AUTOSAR XML (schema 00046)
package /ComponentTypes
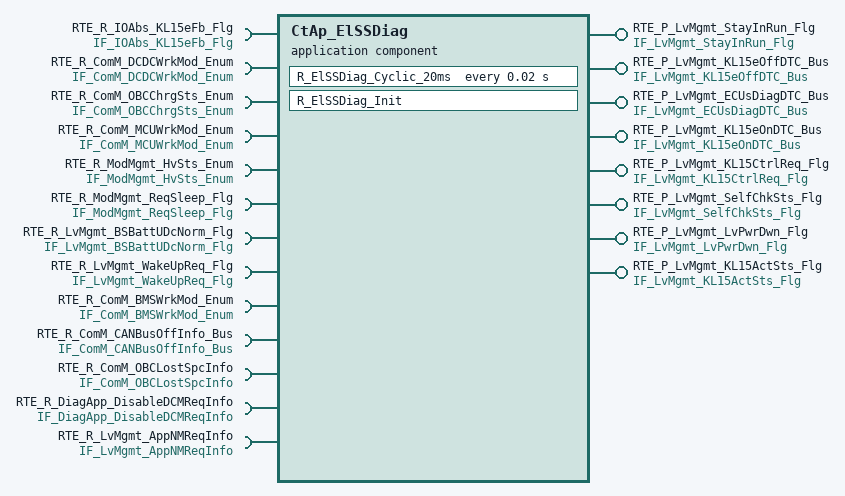
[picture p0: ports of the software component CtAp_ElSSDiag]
  application sw component type CtAp_ElSSDiag
    8 x require port:
      RTE_R_IOAbs_KL15eFb_Flg: nonqueued-receiver-com-spec{data-element=tec_IOAbs_KL15eFb_Flg, filter=data-filter-type=ALWAYS, init-value=0}, required-interface=IF_IOAbs_KL15eFb_Flg
      RTE_R_ComM_DCDCWrkMod_Enum: nonqueued-receiver-com-spec{data-element=tec_ComM_DCDCWrkMod_Enum, filter=data-filter-type=ALWAYS, init-value=0}, required-interface=IF_ComM_DCDCWrkMod_Enum
      RTE_R_ComM_OBCChrgSts_Enum: nonqueued-receiver-com-spec{data-element=tec_ComM_OBCChrgSts_Enum, filter=data-filter-type=ALWAYS, init-value=0}, required-interface=IF_ComM_OBCChrgSts_Enum
      RTE_R_ComM_MCUWrkMod_Enum: nonqueued-receiver-com-spec{data-element=tec_ComM_MCUWrkMod_Enum, filter=data-filter-type=ALWAYS, init-value=0}, required-interface=IF_ComM_MCUWrkMod_Enum
      RTE_R_ModMgmt_HvSts_Enum: nonqueued-receiver-com-spec{data-element=tec_ModMgmt_HvSts_Enum, filter=data-filter-type=ALWAYS, init-value=0}, required-interface=IF_ModMgmt_HvSts_Enum
      RTE_R_ModMgmt_ReqSleep_Flg: nonqueued-receiver-com-spec{data-element=tec_ModMgmt_ReqSleep_Flg, filter=data-filter-type=ALWAYS, init-value=0}, required-interface=IF_ModMgmt_ReqSleep_Flg
      RTE_R_LvMgmt_BSBattUDcNorm_Flg: nonqueued-receiver-com-spec{data-element=tec_LvMgmt_BSBattUDcNorm_Flg, filter=data-filter-type=ALWAYS, init-value=0}, required-interface=IF_LvMgmt_BSBattUDcNorm_Flg
      RTE_R_LvMgmt_WakeUpReq_Flg: nonqueued-receiver-com-spec{data-element=tec_LvMgmt_WakeUpReq_Flg, filter=data-filter-type=ALWAYS, init-value=0}, required-interface=IF_LvMgmt_WakeUpReq_Flg
    8 x provide port:
      RTE_P_LvMgmt_StayInRun_Flg: nonqueued-sender-com-spec{data-element=tec_LvMgmt_StayInRun_Flg, init-value=0}, provided-interface=IF_LvMgmt_StayInRun_Flg
      RTE_P_LvMgmt_KL15eOffDTC_Bus: nonqueued-sender-com-spec{data-element=tec_LvMgmt_KL15eOffDTC_Bus, init-value=fields=[LvMgmt_MonStatKL15eOffDTC:0, LvMgmt_MonResKL15eOffDTC:0, LvMgmt_ErrStatKL15eOffDTC:0, LvMgmt_ErrResKL15eOffDTC:0]}, provided-interface=IF_LvMgmt_KL15eOffDTC_Bus
      RTE_P_LvMgmt_ECUsDiagDTC_Bus: nonqueued-sender-com-spec{data-element=tec_LvMgmt_ECUsDiagDTC_Bus, init-value=fields=[LvMgmt_MonStatECUsDiagDTC:0, LvMgmt_MonResECUsDiagDTC:0, LvMgmt_ErrStatECUsDiagDTC:0, LvMgmt_ErrResECUsDiagDTC:0]}, provided-interface=IF_LvMgmt_ECUsDiagDTC_Bus
      RTE_P_LvMgmt_KL15eOnDTC_Bus: nonqueued-sender-com-spec{data-element=tec_LvMgmt_KL15eOnDTC_Bus, init-value=fields=[LvMgmt_MonStatKL15eOnDTC_:0, LvMgmt_MonResKL15eOnDTC:0, LvMgmt_ErrStatKL15eOnDTC:0, LvMgmt_ErrResKL15eOnDTC:0]}, provided-interface=IF_LvMgmt_KL15eOnDTC_Bus
      RTE_P_LvMgmt_KL15CtrlReq_Flg: nonqueued-sender-com-spec{data-element=tec_LvMgmt_KL15CtrlReq_Flg, init-value=0}, provided-interface=IF_LvMgmt_KL15CtrlReq_Flg
      RTE_P_LvMgmt_SelfChkSts_Flg: nonqueued-sender-com-spec{data-element=tec_LvMgmt_SelfChkSts_Flg, init-value=0}, provided-interface=IF_LvMgmt_SelfChkSts_Flg
      RTE_P_LvMgmt_LvPwrDwn_Flg: nonqueued-sender-com-spec{data-element=tec_LvMgmt_LvPwrDwn_Flg, init-value=0}, provided-interface=IF_LvMgmt_LvPwrDwn_Flg
      RTE_P_LvMgmt_KL15ActSts_Flg: nonqueued-sender-com-spec{data-element=tec_LvMgmt_KL15ActSts_Flg, init-value=0}, provided-interface=IF_LvMgmt_KL15ActSts_Flg
    5 x require port:
      RTE_R_ComM_BMSWrkMod_Enum: nonqueued-receiver-com-spec{data-element=tec_ComM_BMSWrkMod_Enum, filter=data-filter-type=ALWAYS, init-value=0}, required-interface=IF_ComM_BMSWrkMod_Enum
      RTE_R_ComM_CANBusOffInfo_Bus: required-interface=IF_ComM_CANBusOffInfo_Bus
        required-com-specs:
          data-element=tec_ComM_EPTCANBusOffInfo_Bus, filter=data-filter-type=ALWAYS, init-value=fields=[ComM_MonStatEPTCANBusOffInfo:0, ComM_MonResEPTCANBusOffInfo:0, ComM_ErrStatEPTCANBusOffInfo:0, ComM_ErrResEPTCANBusOffInfo:0]
          data-element=tec_ComM_CHCANBusOffInfo_Bus, filter=data-filter-type=ALWAYS, init-value=fields=[ComM_MonStatCHCANBusOffInfo:0, ComM_MonResCHCANBusOffInfo:0, ComM_ErrStatCHCANBusOffInfo:0, ComM_ErrResCHCANBusOffInfo:0]
          data-element=tec_ComM_EPTCANBusOffDTCInfo_Bus, filter=data-filter-type=ALWAYS, init-value=fields=[ComM_MonStatEPTCANBusOffDTCInfo:0, ComM_MonResEPTCANBusOffDTCInfo:0, ComM_ErrStatEPTCANBusOffDTCInfo:0, ComM_ErrResEPTCANBusOffDTCInfo:0]
          data-element=tec_ComM_CHCANBusOffDTCInfo_Bus, filter=data-filter-type=ALWAYS, init-value=fields=[ComM_MonStatCHCANBusOffDTCInfo:0, ComM_MonResCHCANBusOffDTCInfo:0, ComM_ErrStatCHCANBusOffDTCInfo:0, ComM_ErrResCHCANBusOffDTCInfo:0]
          data-element=tec_ComM_DCCANBusOffDTCInfo_Bus, init-value=fields=[ComM_MonStatDCCANDTCBusOffInfo:0, ComM_MonResDCCANDTCBusOffInfo:0, ComM_ErrStatDCCANDTCBusOffInfo:0, ComM_ErrResDCCANDTCBusOffInfo:0]
          data-element=tec_ComM_DCCANBusOffInfo_Bus, init-value=fields=[ComM_MonStatDCCANBusOffInfo:0, ComM_MonResDCCANBusOffInfo:0, ComM_ErrStatDCCANBusOffInfo:0, ComM_ErrResDCCANBusOffInfo:0]
      RTE_R_ComM_OBCLostSpcInfo: nonqueued-receiver-com-spec{data-element=tec_ComM_OBCLostSpcInfo, filter=data-filter-type=ALWAYS, init-value=0}, required-interface=IF_ComM_OBCLostSpcInfo
      RTE_R_DiagApp_DisableDCMReqInfo: nonqueued-receiver-com-spec{data-element=tec_DiagApp_DisableDCMReqInfo, filter=data-filter-type=ALWAYS, init-value=0}, required-interface=IF_DiagApp_DisableDCMReqInfo
      RTE_R_LvMgmt_AppNMReqInfo: nonqueued-receiver-com-spec{data-element=tec_LvMgmt_AppNMReqInfo, filter=data-filter-type=ALWAYS, init-value=0}, required-interface=IF_LvMgmt_AppNMReqInfo
    behavior CtAp_ElSSDiag_InternalBehavior
      timing event TMT_R_ElSSDiag_Cyclic_20ms: start-on-event=R_ElSSDiag_Cyclic_20ms, period=0.02
      init event CtAp_ElSSDiag_InitEvent: start-on-event=R_ElSSDiag_Init
      runnable R_ElSSDiag_Cyclic_20ms
        data-receive-point-by-arguments:
          13 x access:
            REC_RTE_R_ComM_BMSWrkMod_Enum_tec_ComM_BMSWrkMod_Enum: accessed-variable=RTE_R_ComM_BMSWrkMod_Enum.tec_ComM_BMSWrkMod_Enum
            REC_RTE_R_ComM_DCDCWrkMod_Enum_tec_ComM_DCDCWrkMod_Enum: accessed-variable=RTE_R_ComM_DCDCWrkMod_Enum.tec_ComM_DCDCWrkMod_Enum
            REC_RTE_R_ComM_MCUWrkMod_Enum_tec_ComM_MCUWrkMod_Enum: accessed-variable=RTE_R_ComM_MCUWrkMod_Enum.tec_ComM_MCUWrkMod_Enum
            REC_RTE_R_ComM_OBCChrgSts_Enum_tec_ComM_OBCChrgSts_Enum: accessed-variable=RTE_R_ComM_OBCChrgSts_Enum.tec_ComM_OBCChrgSts_Enum
            REC_RTE_R_IOAbs_KL15eFb_Flg_tec_IOAbs_KL15eFb_Flg: accessed-variable=RTE_R_IOAbs_KL15eFb_Flg.tec_IOAbs_KL15eFb_Flg
            REC_RTE_R_LvMgmt_BSBattUDcNorm_Flg_tec_LvMgmt_BSBattUDcNorm_Flg: accessed-variable=RTE_R_LvMgmt_BSBattUDcNorm_Flg.tec_LvMgmt_BSBattUDcNorm_Flg
            REC_RTE_R_LvMgmt_WakeUpReq_Flg_tec_LvMgmt_WakeUpReq_Flg: accessed-variable=RTE_R_LvMgmt_WakeUpReq_Flg.tec_LvMgmt_WakeUpReq_Flg
            REC_RTE_R_ModMgmt_HvSts_Enum_tec_ModMgmt_HvSts_Enum: accessed-variable=RTE_R_ModMgmt_HvSts_Enum.tec_ModMgmt_HvSts_Enum
            REC_RTE_R_ModMgmt_ReqSleep_Flg_tec_ModMgmt_ReqSleep_Flg: accessed-variable=RTE_R_ModMgmt_ReqSleep_Flg.tec_ModMgmt_ReqSleep_Flg
            REC_RTE_R_ComM_CANBusOffInfo_Bus_tec_ComM_EPTCANBusOffInfo_Bus: accessed-variable=RTE_R_ComM_CANBusOffInfo_Bus.tec_ComM_EPTCANBusOffInfo_Bus
            REC_RTE_R_ComM_OBCLostSpcInfo_tec_ComM_OBCLostSpcInfo: accessed-variable=RTE_R_ComM_OBCLostSpcInfo.tec_ComM_OBCLostSpcInfo
            REC_RTE_R_DiagApp_DisableDCMReqInfo_tec_DiagApp_DisableDCMReqInfo: accessed-variable=RTE_R_DiagApp_DisableDCMReqInfo.tec_DiagApp_DisableDCMReqInfo
            REC_RTE_R_LvMgmt_AppNMReqInfo_tec_LvMgmt_AppNMReqInfo: accessed-variable=RTE_R_LvMgmt_AppNMReqInfo.tec_LvMgmt_AppNMReqInfo
        data-send-points:
          8 x access:
            SEND_RTE_P_LvMgmt_ECUsDiagDTC_Bus_tec_LvMgmt_ECUsDiagDTC_Bus: accessed-variable=RTE_P_LvMgmt_ECUsDiagDTC_Bus.tec_LvMgmt_ECUsDiagDTC_Bus
            SEND_RTE_P_LvMgmt_KL15ActSts_Flg_tec_LvMgmt_KL15ActSts_Flg: accessed-variable=RTE_P_LvMgmt_KL15ActSts_Flg.tec_LvMgmt_KL15ActSts_Flg
            SEND_RTE_P_LvMgmt_KL15CtrlReq_Flg_tec_LvMgmt_KL15CtrlReq_Flg: accessed-variable=RTE_P_LvMgmt_KL15CtrlReq_Flg.tec_LvMgmt_KL15CtrlReq_Flg
            SEND_RTE_P_LvMgmt_KL15eOffDTC_Bus_tec_LvMgmt_KL15eOffDTC_Bus: accessed-variable=RTE_P_LvMgmt_KL15eOffDTC_Bus.tec_LvMgmt_KL15eOffDTC_Bus
            SEND_RTE_P_LvMgmt_KL15eOnDTC_Bus_tec_LvMgmt_KL15eOnDTC_Bus: accessed-variable=RTE_P_LvMgmt_KL15eOnDTC_Bus.tec_LvMgmt_KL15eOnDTC_Bus
            SEND_RTE_P_LvMgmt_LvPwrDwn_Flg_tec_LvMgmt_LvPwrDwn_Flg: accessed-variable=RTE_P_LvMgmt_LvPwrDwn_Flg.tec_LvMgmt_LvPwrDwn_Flg
            SEND_RTE_P_LvMgmt_SelfChkSts_Flg_tec_LvMgmt_SelfChkSts_Flg: accessed-variable=RTE_P_LvMgmt_SelfChkSts_Flg.tec_LvMgmt_SelfChkSts_Flg
            SEND_RTE_P_LvMgmt_StayInRun_Flg_tec_LvMgmt_StayInRun_Flg: accessed-variable=RTE_P_LvMgmt_StayInRun_Flg.tec_LvMgmt_StayInRun_Flg
      runnable R_ElSSDiag_Init
  swc implementation CtAp_ElSSDiag_Implementation: behavior=CtAp_ElSSDiag_InternalBehavior
